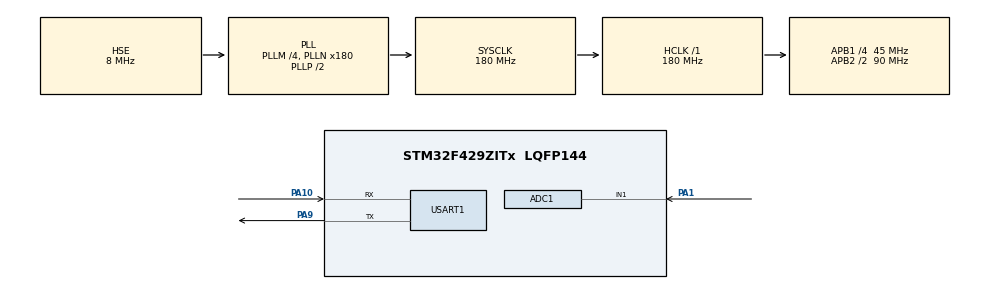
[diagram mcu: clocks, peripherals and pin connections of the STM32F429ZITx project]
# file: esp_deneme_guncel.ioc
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ADC1.Channel-0\#ChannelRegularConversion=ADC_CHANNEL_1
ADC1.ContinuousConvMode=ENABLE
ADC1.NbrOfConversionFlag=1
ADC1.Rank-0\#ChannelRegularConversion=1
ADC1.SamplingTime-0\#ChannelRegularConversion=ADC_SAMPLETIME_3CYCLES
ADC1.master=1
Mcu.Family=STM32F4
Mcu.Name=STM32F429ZITx
Mcu.Package=LQFP144
NVIC.PriorityGroup=NVIC_PRIORITYGROUP_0
NVIC.TIM1_UP_TIM10_IRQn=true\:0\:0\:false\:false\:true\:false\:true
NVIC.TimeBase=TIM1_UP_TIM10_IRQn
NVIC.TimeBaseIP=TIM1
NVIC.USART1_IRQn=true\:0\:0\:false\:false\:true\:true\:true
PA1.Signal=ADCx_IN1
PA10.Mode=Asynchronous
PA10.Signal=USART1_RX
PA9.Mode=Asynchronous
PA9.Signal=USART1_TX
PH0/OSC_IN.Mode=HSE-External-Oscillator
PH0/OSC_IN.Signal=RCC_OSC_IN
PH1/OSC_OUT.Mode=HSE-External-Oscillator
PH1/OSC_OUT.Signal=RCC_OSC_OUT
ProjectManager.HeapSize=0x200
ProjectManager.StackSize=0x400
ProjectManager.TargetToolchain=STM32CubeIDE
RCC.48MHZClocksFreq_Value=51428571.428571425
RCC.AHBFreq_Value=180000000
RCC.APB1CLKDivider=RCC_HCLK_DIV4
RCC.APB1Freq_Value=45000000
RCC.APB1TimFreq_Value=90000000
RCC.APB2CLKDivider=RCC_HCLK_DIV2
RCC.APB2Freq_Value=90000000
RCC.APB2TimFreq_Value=180000000
RCC.CortexFreq_Value=180000000
RCC.HCLKFreq_Value=180000000
RCC.HSE_VALUE=8000000
RCC.HSI_VALUE=16000000
RCC.LSE_VALUE=32768
RCC.PLLM=4
RCC.PLLN=180
RCC.PLLQ=7
RCC.PLLSourceVirtual=RCC_PLLSOURCE_HSE
RCC.SYSCLKFreq_VALUE=180000000
RCC.SYSCLKSource=RCC_SYSCLKSOURCE_PLLCLK
RCC.VCOOutputFreq_Value=360000000
SH.ADCx_IN1.0=ADC1_IN1,IN1
USART1.VirtualMode=VM_ASYNC
VP_SYS_VS_tim1.Mode=TIM1
board=STM32F429I-DISC1

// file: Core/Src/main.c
/* USER CODE BEGIN Header */
/**
  ******************************************************************************
  * @file           : main.c
  * @brief          : Main program body
  ******************************************************************************
  * @attention
  *
  * <h2><center>&copy; Copyright (c) 2021 STMicroelectronics.
  * All rights reserved.</center></h2>
  *
  * This software component is licensed by ST under BSD 3-Clause license,
  * the "License"; You may not use this file except in compliance with the
  * License. You may obtain a copy of the License at:
  *                        opensource.org/licenses/BSD-3-Clause
  *
  * Written by GURKAN TOPKARA - 16.12.2021
  * gurkantopkara7@gmail.com
  ******************************************************************************
  */
/* USER CODE END Header */
#include "main.h"
#include "stm32f4xx_hal_uart.h"

ADC_HandleTypeDef hadc1;

UART_HandleTypeDef huart1;

void SystemClock_Config(void);
static void MX_GPIO_Init(void);
static void MX_ADC1_Init(void);
static void MX_USART1_UART_Init(void);

/* USER CODE BEGIN 0 */
char sendBuff[80], sendBuff2[80],rx_buffer [40];
uint8_t recArr[80], recData;
uint8_t buffLen, buffLen2, buffCnt = 0;
uint16_t ADC_Value ;

const char API_KEY[] = 		"A1WNV4DDSG49HSBE"; // API KEY FROM  YOUR THINGSPEAKS PAGE
const char WIFI_NAME[] = 	"elfo11"; // Your wifi name
const char WIFI_PASSW[] = 	"elfotopkara11"; // Your password

int count=1;
 void ADC_Get_Value ()
{

	HAL_ADC_Start(&hadc1);

	if(HAL_ADC_PollForConversion(&hadc1,10000) == HAL_OK)
	{
		ADC_Value = HAL_ADC_GetValue(&hadc1);

	}
	HAL_ADC_Stop(&hadc1);
}

void HAL_UART_RxCpltCallback(UART_HandleTypeDef *huart)
{
	recArr[buffCnt++] = recData;
	if(buffCnt == 80) buffCnt = 0;
	HAL_UART_Receive_IT(&huart1, &recData, 1);
}

/* USER CODE END 0 */

int main(void)
{

  /* MCU Configuration--------------------------------------------------------*/

  /* Reset of all peripherals, Initializes the Flash interface and the Systick. */
  HAL_Init();

  /* Configure the system clock */
  SystemClock_Config();

  /* Initialize all configured peripherals */
  MX_GPIO_Init();
  MX_ADC1_Init();
  MX_USART1_UART_Init();
  /* USER CODE BEGIN 2 */

  // Wifi Connection

  buffLen = sprintf(sendBuff, "AT\r\n");
  HAL_UART_Transmit(&huart1, (uint8_t *)sendBuff, buffLen, 1000);
  HAL_Delay(2000);
  buffLen = sprintf(sendBuff, "ATE0\r\n");
  HAL_UART_Transmit(&huart1, (uint8_t *)sendBuff, buffLen, 1000);
  HAL_Delay(2000);
  buffLen = sprintf(sendBuff, "AT+CWQAP\r\n");
  HAL_UART_Transmit(&huart1, (uint8_t *)sendBuff, buffLen, 1000);
  HAL_Delay(2000);
  buffLen = sprintf(sendBuff, "AT+CWMODE=3\r\n");
  HAL_UART_Transmit(&huart1, (uint8_t *)sendBuff, buffLen, 1000);
  HAL_Delay(2000);
  buffLen = sprintf(sendBuff, "AT+CIPMODE=0\r\n");
  HAL_UART_Transmit(&huart1, (uint8_t *)sendBuff, buffLen, 1000);
  HAL_Delay(2000);
  buffLen = sprintf(sendBuff, "AT+CIPMUX=1\r\n");
  HAL_UART_Transmit(&huart1, (uint8_t *)sendBuff, buffLen, 1000);
  HAL_Delay(2000);

  buffLen = sprintf(sendBuff, "AT+CWDHCP=1,1\r\n");
  HAL_UART_Transmit(&huart1, (uint8_t *)sendBuff, buffLen, 1000);

  HAL_Delay(4000);

  buffLen = sprintf(sendBuff, "AT+CWLAP\r\n");
  HAL_UART_Transmit(&huart1, (uint8_t *)sendBuff, buffLen, 1000);
  HAL_Delay(3000);
  buffLen = sprintf(sendBuff, "AT+CWJAP=\"%s\",\"%s\"\r\n", WIFI_NAME, WIFI_PASSW);
  HAL_UART_Transmit(&huart1, (uint8_t *)sendBuff, buffLen, 1000);
  HAL_Delay(10000);
  buffLen = sprintf(sendBuff, "AT+RST\r\n");
  HAL_UART_Transmit(&huart1, (uint8_t *)sendBuff, buffLen, 1000);
  HAL_Delay(12000);

  /* USER CODE END 2 */

  /* Infinite loop */
  /* USER CODE BEGIN WHILE */
  while (1)
  {
	  ADC_Get_Value();

	  //Value_Buf[0] = ADC_Value;
	  //Value_Buf[1] = Voltage;
    /* USER CODE END WHILE */
	  // connect Thinkspeak server*/

	  buffLen = sprintf(sendBuff, "AT+CIPSTART=\"TCP\",\"184.106.153.149\",80\r\n");
	  HAL_UART_Transmit(&huart1, (uint8_t *)sendBuff, buffLen, 1000);
	  HAL_Delay(5000); // 8 idi
	  ADC_Get_Value();
	  // after connection to Thingspeak prepare data to send

	  buffLen = sprintf(sendBuff,"GET /update?api_key=A1WNV4DDSG49HSBE&field1=%u&field2=%d\r\n",ADC_Value,count); // ESP8266 sends the data to server by using this code.
	  buffLen2 = sprintf(sendBuff2, "AT+CIPSEND=%d\r\n", buffLen);

	  // send preapeared buffers to Thingspeak using ESP8266
	  HAL_UART_Transmit(&huart1, (uint8_t *)sendBuff2, buffLen2, 1000);
	  HAL_Delay(7000);
	  HAL_UART_Transmit(&huart1, (uint8_t *)sendBuff, buffLen, 1000);
	  count++;
	  HAL_Delay(7000);

	  // wait for 15sn to send new data
	  //HAL_Delay(10000);
	//  buffLen = sprintf(sendBuff, "AT+RST\r\n");
	 // HAL_UART_Transmit(&huart1, (uint8_t *)sendBuff, buffLen, 1000);
	 // HAL_Delay(12000);
  }
}

void SystemClock_Config(void)
{
  RCC_OscInitTypeDef RCC_OscInitStruct = {0};
  RCC_ClkInitTypeDef RCC_ClkInitStruct = {0};

  /** Configure the main internal regulator output voltage
  */
  __HAL_RCC_PWR_CLK_ENABLE();
  __HAL_PWR_VOLTAGESCALING_CONFIG(PWR_REGULATOR_VOLTAGE_SCALE1);
  /** Initializes the RCC Oscillators according to the specified parameters
  * in the RCC_OscInitTypeDef structure.
  */
  RCC_OscInitStruct.OscillatorType = RCC_OSCILLATORTYPE_HSE;
  RCC_OscInitStruct.HSEState = RCC_HSE_ON;
  RCC_OscInitStruct.PLL.PLLState = RCC_PLL_ON;
  RCC_OscInitStruct.PLL.PLLSource = RCC_PLLSOURCE_HSE;
  RCC_OscInitStruct.PLL.PLLM = 4;
  RCC_OscInitStruct.PLL.PLLN = 180;
  RCC_OscInitStruct.PLL.PLLP = RCC_PLLP_DIV2;
  RCC_OscInitStruct.PLL.PLLQ = 7;
  if (HAL_RCC_OscConfig(&RCC_OscInitStruct) != HAL_OK)
  {
    Error_Handler();
  }
  /** Activate the Over-Drive mode
  */
  if (HAL_PWREx_EnableOverDrive() != HAL_OK)
  {
    Error_Handler();
  }
  /** Initializes the CPU, AHB and APB buses clocks
  */
  RCC_ClkInitStruct.ClockType = RCC_CLOCKTYPE_HCLK|RCC_CLOCKTYPE_SYSCLK
                              |RCC_CLOCKTYPE_PCLK1|RCC_CLOCKTYPE_PCLK2;
  RCC_ClkInitStruct.SYSCLKSource = RCC_SYSCLKSOURCE_PLLCLK;
  RCC_ClkInitStruct.AHBCLKDivider = RCC_SYSCLK_DIV1;
  RCC_ClkInitStruct.APB1CLKDivider = RCC_HCLK_DIV4;
  RCC_ClkInitStruct.APB2CLKDivider = RCC_HCLK_DIV2;

  if (HAL_RCC_ClockConfig(&RCC_ClkInitStruct, FLASH_LATENCY_5) != HAL_OK)
  {
    Error_Handler();
  }
}

static void MX_ADC1_Init(void)
{

  ADC_ChannelConfTypeDef sConfig = {0};

  /** Configure the global features of the ADC (Clock, Resolution, Data Alignment and number of conversion)
  */
  hadc1.Instance = ADC1;
  hadc1.Init.ClockPrescaler = ADC_CLOCK_SYNC_PCLK_DIV4;
  hadc1.Init.Resolution = ADC_RESOLUTION_12B;
  hadc1.Init.ScanConvMode = DISABLE;
  hadc1.Init.ContinuousConvMode = ENABLE;
  hadc1.Init.DiscontinuousConvMode = DISABLE;
  hadc1.Init.ExternalTrigConvEdge = ADC_EXTERNALTRIGCONVEDGE_NONE;
  hadc1.Init.ExternalTrigConv = ADC_SOFTWARE_START;
  hadc1.Init.DataAlign = ADC_DATAALIGN_RIGHT;
  hadc1.Init.NbrOfConversion = 1;
  hadc1.Init.DMAContinuousRequests = DISABLE;
  hadc1.Init.EOCSelection = ADC_EOC_SINGLE_CONV;
  if (HAL_ADC_Init(&hadc1) != HAL_OK)
  {
    Error_Handler();
  }
  /** Configure for the selected ADC regular channel its corresponding rank in the sequencer and its sample time.
  */
  sConfig.Channel = ADC_CHANNEL_1;
  sConfig.Rank = 1;
  sConfig.SamplingTime = ADC_SAMPLETIME_3CYCLES;
  if (HAL_ADC_ConfigChannel(&hadc1, &sConfig) != HAL_OK)
  {
    Error_Handler();
  }

}

static void MX_USART1_UART_Init(void)
{

  huart1.Instance = USART1;
  huart1.Init.BaudRate = 115200;
  huart1.Init.WordLength = UART_WORDLENGTH_8B;
  huart1.Init.StopBits = UART_STOPBITS_1;
  huart1.Init.Parity = UART_PARITY_NONE;
  huart1.Init.Mode = UART_MODE_TX_RX;
  huart1.Init.HwFlowCtl = UART_HWCONTROL_NONE;
  huart1.Init.OverSampling = UART_OVERSAMPLING_16;
  if (HAL_UART_Init(&huart1) != HAL_OK)
  {
    Error_Handler();
  }

}

static void MX_GPIO_Init(void)
{

  /* GPIO Ports Clock Enable */
  __HAL_RCC_GPIOH_CLK_ENABLE();
  __HAL_RCC_GPIOA_CLK_ENABLE();

}

void HAL_TIM_PeriodElapsedCallback(TIM_HandleTypeDef *htim)
{
  if (htim->Instance == TIM1) {
    HAL_IncTick();
  }
}

void Error_Handler(void)
{
  __disable_irq();
  while (1)
  {
  }
}

/************************ (C) COPYRIGHT STMicroelectronics *****END OF FILE****/
